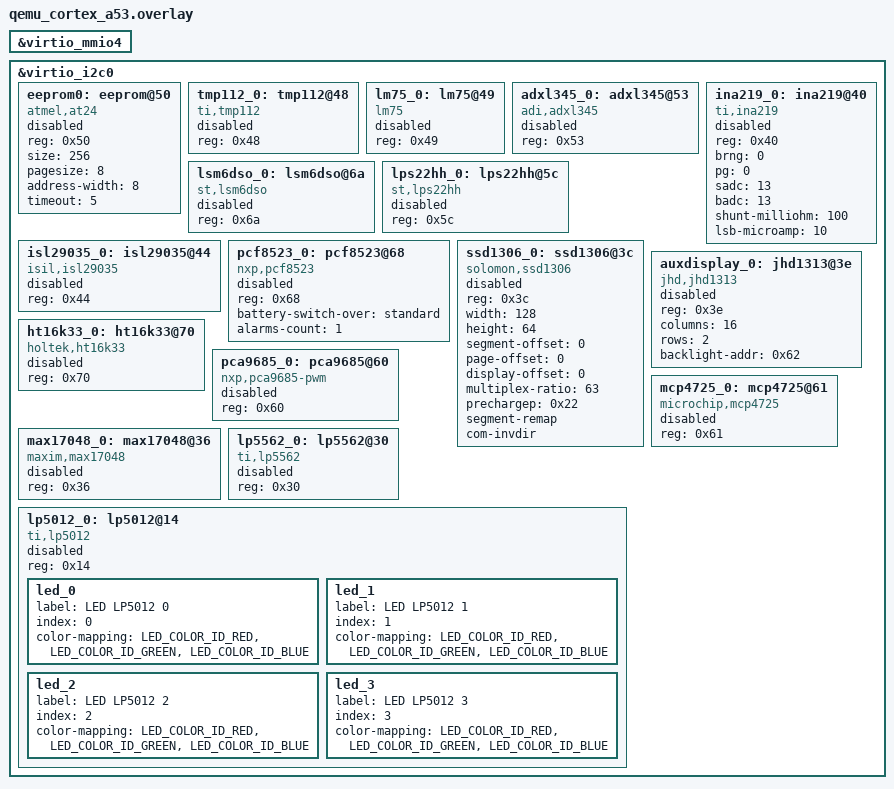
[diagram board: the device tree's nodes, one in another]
/*
 * Copyright (c) 2026
 * SPDX-License-Identifier: Apache-2.0
 *
 * Turn on the Cortex-A53's VIRTIO I2C adapter and describe the chips the
 * browser has on the bus. The node itself is declared (disabled) by the
 * browser_bridge shield, whose overlay documents the slot and the QEMU side.
 *
 * The chips are page-side models (src/virtio/devices/), so this overlay and
 * src/virtio/index.ts have to agree on what is soldered where. A node whose
 * address the page is not answering for simply fails to bind — a chip the page
 * detaches NAKs exactly like one that fell off the board.
 *
 * **Every chip below is declared `status = "disabled"`.** This file is the
 * parts bin: it says what the browser can model and at which address, and a
 * `<part>-only` snippet is what solders one onto a given image. `-S i2c-shell`
 * fits the whole set the shell's commands can drive.
 *
 * It used to be the other way round — five chips okay by default and a growing
 * disable-list at the top of every `-only` snippet. That cost twelve stanzas
 * per snippet, went stale (lsm6dso-only never disabled the EEPROM or the OLED,
 * pcf8523-only did), and put an EEPROM, two thermometers and an OLED in the
 * dock of every sample that wanted one accelerometer. Opt-in is O(1) per
 * snippet and cannot drift: a part is on this bus only where it is asked for.
 *
 * Snippet overlays are applied after the shield's, so virtio_i2c0 already
 * exists by the time this runs; and snippets are applied in command-line
 * order, so `-S virtio-i2c` must come before the `-only` snippet that enables
 * a chip declared here.
 */

#include <zephyr/dt-bindings/led/led.h>

&virtio_mmio4 {
	status = "okay";
};

&virtio_i2c0 {
	status = "okay";

	/*
	 * Matches createAt24({ address: 0x50 }) in src/virtio/index.ts. The
	 * page models one-byte word addressing, which is the AT24C02 part.
	 * `-S eeprom-only`, which also adds the eeprom-0 alias.
	 */
	eeprom0: eeprom@50 {
		compatible = "atmel,at24";
		reg = <0x50>;
		size = <256>;
		pagesize = <8>;
		address-width = <8>;
		timeout = <5>;
		status = "disabled";
	};

	/*
	 * Matches createTmp112({ address: 0x48 }) in src/virtio/index.ts, whose
	 * temperature its sensor card drives directly. Zephyr's stock ti,tmp112
	 * binds to it and talks over the real bus — `sensor get tmp112@48` reads a
	 * value the page made up, through an unmodified in-tree driver. No sample
	 * of its own; `-S i2c-shell` is what puts it on the bus.
	 */
	tmp112_0: tmp112@48 {
		compatible = "ti,tmp112";
		reg = <0x48>;
		status = "disabled";
	};

	/*
	 * Matches createLm75({ address: 0x49 }) in src/virtio/index.ts — a
	 * second, simpler temperature part one strap along, so both share the
	 * bus. `sensor get lm75@49` reads it through Zephyr's stock driver.
	 * Like the TMP112, it rides `-S i2c-shell`: two thermometers on one bus
	 * is a shell story (`i2c scan` finds both), not a demo of its own.
	 */
	lm75_0: lm75@49 {
		compatible = "lm75";
		reg = <0x49>;
		status = "disabled";
	};

	/*
	 * Matches createAdxl345({ address: 0x53 }) in src/virtio/index.ts: a
	 * 3-axis accelerometer whose card can follow the device's own tilt.
	 * `-S adxl345-only` turns it on and aliases it accel0, which is how the
	 * LVGL accelerometer_chart sample reads it unmodified; `-S i2c-shell`
	 * also carries it, for `sensor get adxl345@53`.
	 */
	adxl345_0: adxl345@53 {
		compatible = "adi,adxl345";
		reg = <0x53>;
		status = "disabled";
	};

	/*
	 * Enable any of the parts below with:
	 *   -S i2c-shell   (the whole set the shell's commands can drive)
	 *   -S adxl345-only / eeprom-only / lsm6dso-only / lps22hh-only /
	 *      ina219-only / isl29035-only / pcf8523-only / jhd1313-only /
	 *      ht16k33-only / lp5562-only / lp5012-only / pca9685-only /
	 *      mcp4725-only / max17048-only
	 *      (dedicated sample: that part alone, nothing else on the bus)
	 *
	 * The page attaches matching TypeScript models only while these nodes
	 * are okay — see syncManagedChips in src/virtio/index.ts.
	 */
	lsm6dso_0: lsm6dso@6a {
		compatible = "st,lsm6dso";
		reg = <0x6a>;
		status = "disabled";
	};

	lps22hh_0: lps22hh@5c {
		compatible = "st,lps22hh";
		reg = <0x5c>;
		status = "disabled";
	};

	ina219_0: ina219@40 {
		compatible = "ti,ina219";
		reg = <0x40>;
		brng = <0>;
		pg = <0>;
		sadc = <13>;
		badc = <13>;
		shunt-milliohm = <100>;
		lsb-microamp = <10>;
		status = "disabled";
	};

	isl29035_0: isl29035@44 {
		compatible = "isil,isl29035";
		reg = <0x44>;
		status = "disabled";
	};

	/*
	 * NXP PCF8523 RTC (Adafruit shield address 0x68). The shell reaches it
	 * via -S i2c-shell; the dedicated samples/drivers/rtc build uses
	 * -S pcf8523-only, which also adds the `rtc` alias it binds.
	 */
	pcf8523_0: pcf8523@68 {
		compatible = "nxp,pcf8523";
		reg = <0x68>;
		battery-switch-over = "standard";
		alarms-count = <1>;
		status = "disabled";
	};

	/*
	 * Matches createSsd1306({ address: 0x3c }) in src/virtio/index.ts, whose
	 * GDDRAM the OLED panel paints onto a canvas. `-S oled` is what turns it
	 * on, and it repoints zephyr,display here at the same time — the board is
	 * otherwise on ramfb. Nothing but a display driver can drive an OLED, so
	 * there is no build where the panel is worth carrying dark.
	 *
	 * The timing and charge-pump properties are the datasheet's defaults; the
	 * page ignores them, but they are required by the binding and a real part
	 * would need them.
	 */
	ssd1306_0: ssd1306@3c {
		compatible = "solomon,ssd1306";
		reg = <0x3c>;
		width = <128>;
		height = <64>;
		segment-offset = <0>;
		page-offset = <0>;
		display-offset = <0>;
		multiplex-ratio = <63>;
		prechargep = <0x22>;
		segment-remap;
		com-invdir;
		status = "disabled";
	};

	/*
	 * Grove RGB character LCD. Matches createJhd1313Pair() in
	 * src/virtio/index.ts (LCD @0x3e, backlight-addr 0x62). Disabled by
	 * default so everyday builds stay on ramfb / OLED; samples/drivers/
	 * auxdisplay uses -S jhd1313-only.
	 *
	 * Nodename auxdisplay_0 is required: the stock sample binds
	 * DT_NODELABEL(auxdisplay_0).
	 */
	auxdisplay_0: jhd1313@3e {
		compatible = "jhd,jhd1313";
		reg = <0x3e>;
		columns = <16>;
		rows = <2>;
		backlight-addr = <0x62>;
		status = "disabled";
	};

	/*
	 * Holtek HT16K33 16×8 LED matrix. Matches createHt16k33({ address: 0x70 })
	 * in src/virtio/index.ts. Disabled by default; samples/drivers/ht16k33
	 * uses -S ht16k33-only. Keyscan / irq-gpios are omitted (v1 is LED only).
	 */
	ht16k33_0: ht16k33@70 {
		compatible = "holtek,ht16k33";
		reg = <0x70>;
		status = "disabled";
	};

	/*
	 * NXP PCA9685 16-channel PWM. Matches createPca9685({ address: 0x60 }) in
	 * src/virtio/index.ts. Adafruit's shield defaults to 0x40, but that address
	 * is already ina219@40 here — use 0x60 so both can stay declared.
	 * samples/drivers/led/pwm uses -S pca9685-only.
	 */
	pca9685_0: pca9685@60 {
		compatible = "nxp,pca9685-pwm";
		reg = <0x60>;
		#pwm-cells = <3>;
		status = "disabled";
	};

	/*
	 * Microchip MCP4725 12-bit DAC. Matches createMcp4725({ address: 0x61 }) in
	 * src/virtio/index.ts. Adafruit breakouts default to 0x60, but that address
	 * is already pca9685@60 here — use 0x61 (A0 high) so both can stay declared.
	 * samples/drivers/dac uses -S mcp4725-only.
	 */
	mcp4725_0: mcp4725@61 {
		compatible = "microchip,mcp4725";
		reg = <0x61>;
		#io-channel-cells = <1>;
		status = "disabled";
	};

	/*
	 * Maxim MAX17048 Li-ion fuel gauge. Matches createMax17048({ address: 0x36 })
	 * in src/virtio/index.ts (Adafruit / Zephyr shield default). Disabled by
	 * default; samples/drivers/fuel_gauge uses -S max17048-only.
	 */
	max17048_0: max17048@36 {
		compatible = "maxim,max17048";
		reg = <0x36>;
		status = "disabled";
	};

	/*
	 * TI LP5562 RGBW LED driver. Matches createLp5562({ address: 0x30 }) in
	 * src/virtio/index.ts (Zephyr sample default). Disabled by default;
	 * samples/drivers/led/lp5562 uses -S lp5562-only. enable-gpios omitted —
	 * the page model treats the chip as already enabled.
	 */
	lp5562_0: lp5562@30 {
		compatible = "ti,lp5562";
		reg = <0x30>;
		status = "disabled";
	};

	/*
	 * TI LP5012 4-module RGB LED. Matches createLp5012({ address: 0x14 }) in
	 * src/virtio/index.ts. Address 0x14 is the LP5009/12 binding example and
	 * avoids lp5562@30. Disabled by default; samples/drivers/led/lp50xx uses
	 * -S lp5012-only. enable-gpios omitted.
	 */
	lp5012_0: lp5012@14 {
		compatible = "ti,lp5012";
		reg = <0x14>;
		status = "disabled";

		led_0 {
			label = "LED LP5012 0";
			index = <0>;
			color-mapping = <LED_COLOR_ID_RED>,
					 <LED_COLOR_ID_GREEN>,
					 <LED_COLOR_ID_BLUE>;
		};

		led_1 {
			label = "LED LP5012 1";
			index = <1>;
			color-mapping = <LED_COLOR_ID_RED>,
					 <LED_COLOR_ID_GREEN>,
					 <LED_COLOR_ID_BLUE>;
		};

		led_2 {
			label = "LED LP5012 2";
			index = <2>;
			color-mapping = <LED_COLOR_ID_RED>,
					 <LED_COLOR_ID_GREEN>,
					 <LED_COLOR_ID_BLUE>;
		};

		led_3 {
			label = "LED LP5012 3";
			index = <3>;
			color-mapping = <LED_COLOR_ID_RED>,
					 <LED_COLOR_ID_GREEN>,
					 <LED_COLOR_ID_BLUE>;
		};
	};
};

/*
 * No aliases here. accel0 and eeprom-0 used to live at the bottom of this file
 * because the parts they name were on the bus unconditionally. Now that the
 * parts are opt-in, each alias travels with the snippet that solders its chip
 * on — accel0 in adxl345-only, eeprom-0 in eeprom-only, rtc in pcf8523-only,
 * fuel-gauge0 in max17048-only. Same rule that kept them out of the shield:
 * a build resolves DT_ALIAS(...) to a real, driver-bound node, or carries no
 * such name at all.
 */
